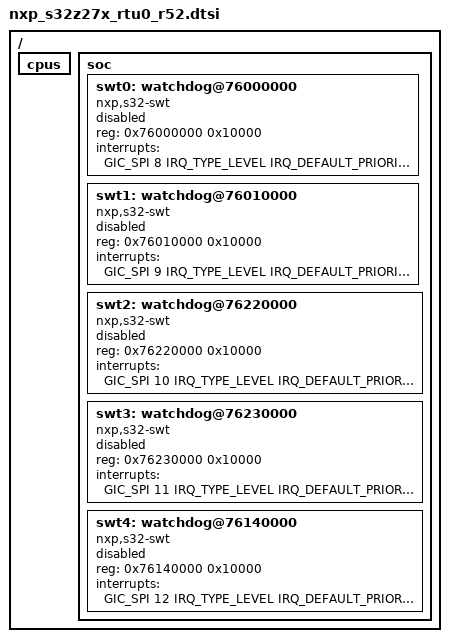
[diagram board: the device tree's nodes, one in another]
/*
 * Copyright 2022 NXP
 *
 * SPDX-License-Identifier: Apache-2.0
 */

#include <arm/nxp/nxp_s32z27x_r52.dtsi>

/ {

	cpus {
		/delete-node/ cpu@4;
		/delete-node/ cpu@5;
		/delete-node/ cpu@6;
		/delete-node/ cpu@7;
	};

	soc {
		swt0: watchdog@76000000 {
			compatible = "nxp,s32-swt";
			reg = <0x76000000 0x10000>;
			interrupts = <GIC_SPI 8 IRQ_TYPE_LEVEL IRQ_DEFAULT_PRIORITY>;
			status = "disabled";
		};

		swt1: watchdog@76010000 {
			compatible = "nxp,s32-swt";
			reg = <0x76010000 0x10000>;
			interrupts = <GIC_SPI 9 IRQ_TYPE_LEVEL IRQ_DEFAULT_PRIORITY>;
			status = "disabled";
		};

		swt2: watchdog@76220000 {
			compatible = "nxp,s32-swt";
			reg = <0x76220000 0x10000>;
			interrupts = <GIC_SPI 10 IRQ_TYPE_LEVEL IRQ_DEFAULT_PRIORITY>;
			status = "disabled";
		};

		swt3: watchdog@76230000 {
			compatible = "nxp,s32-swt";
			reg = <0x76230000 0x10000>;
			interrupts = <GIC_SPI 11 IRQ_TYPE_LEVEL IRQ_DEFAULT_PRIORITY>;
			status = "disabled";
		};

		swt4: watchdog@76140000 {
			compatible = "nxp,s32-swt";
			reg = <0x76140000 0x10000>;
			interrupts = <GIC_SPI 12 IRQ_TYPE_LEVEL IRQ_DEFAULT_PRIORITY>;
			status = "disabled";
		};
	};
};
